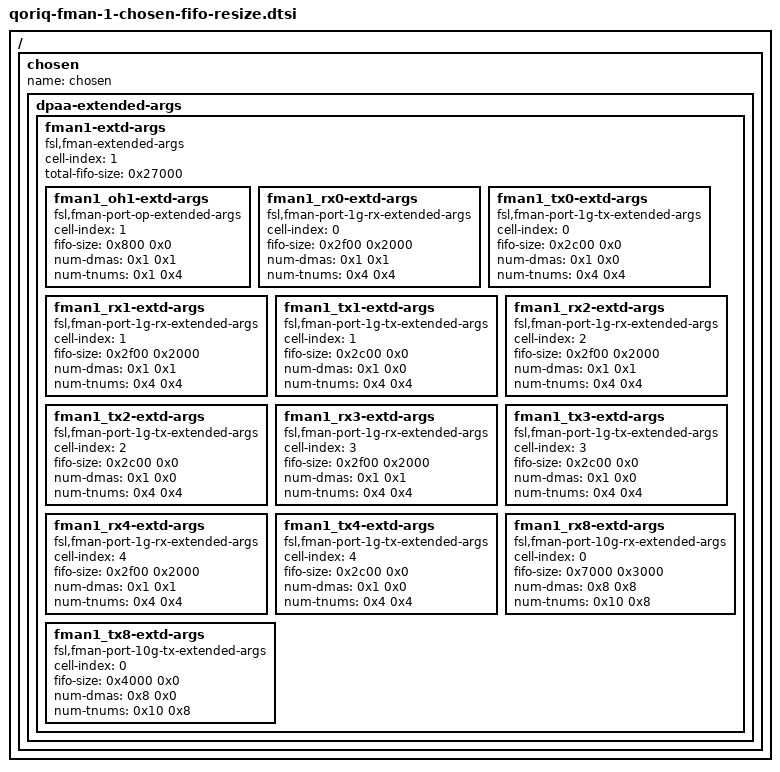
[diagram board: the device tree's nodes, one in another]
// SPDX-License-Identifier: (GPL-2.0+ OR BSD-3-Clause)
/*
 * Copyright 2018 NXP
 */

/ {
	chosen {
		name = "chosen";
		dpaa-extended-args {
			fman1-extd-args {
				cell-index = <1>;
				compatible = "fsl,fman-extended-args";
				total-fifo-size = <0x27000>;
				fman1_oh1-extd-args {
					cell-index = <1>;
					compatible = "fsl,fman-port-op-extended-args";
					fifo-size = <0x800 0x0>;
					num-dmas = <0x1 0x1>;
					num-tnums = <0x1 0x4>;
				};
				fman1_rx0-extd-args {
					cell-index = <0>;
					compatible = "fsl,fman-port-1g-rx-extended-args";
					fifo-size = <0x2f00 0x2000>;
					num-dmas = <0x1 0x1>;
					num-tnums = <0x4 0x4>;
				};
				fman1_tx0-extd-args {
					cell-index = <0>;
					compatible = "fsl,fman-port-1g-tx-extended-args";
					fifo-size = <0x2c00 0x0>;
					num-dmas = <0x1 0x0>;
					num-tnums = <0x4 0x4>;
				};
				fman1_rx1-extd-args {
					cell-index = <1>;
					compatible = "fsl,fman-port-1g-rx-extended-args";
					fifo-size = <0x2f00 0x2000>;
					num-dmas = <0x1 0x1>;
					num-tnums = <0x4 0x4>;
				};
				fman1_tx1-extd-args {
					cell-index = <1>;
					compatible = "fsl,fman-port-1g-tx-extended-args";
					fifo-size = <0x2c00 0x0>;
					num-dmas = <0x1 0x0>;
					num-tnums = <0x4 0x4>;
				};
				fman1_rx2-extd-args {
					cell-index = <2>;
					compatible = "fsl,fman-port-1g-rx-extended-args";
					fifo-size = <0x2f00 0x2000>;
					num-dmas = <0x1 0x1>;
					num-tnums = <0x4 0x4>;
				};
				fman1_tx2-extd-args {
					cell-index = <2>;
					compatible = "fsl,fman-port-1g-tx-extended-args";
					fifo-size = <0x2c00 0x0>;
					num-dmas = <0x1 0x0>;
					num-tnums = <0x4 0x4>;
				};
				fman1_rx3-extd-args {
					cell-index = <3>;
					compatible = "fsl,fman-port-1g-rx-extended-args";
					fifo-size = <0x2f00 0x2000>;
					num-dmas = <0x1 0x1>;
					num-tnums = <0x4 0x4>;
				};
				fman1_tx3-extd-args {
					cell-index = <3>;
					compatible = "fsl,fman-port-1g-tx-extended-args";
					fifo-size = <0x2c00 0x0>;
					num-dmas = <0x1 0x0>;
					num-tnums = <0x4 0x4>;
				};
				fman1_rx4-extd-args {
					cell-index = <4>;
					compatible = "fsl,fman-port-1g-rx-extended-args";
					fifo-size = <0x2f00 0x2000>;
					num-dmas = <0x1 0x1>;
					num-tnums = <0x4 0x4>;
				};
				fman1_tx4-extd-args {
					cell-index = <4>;
					compatible = "fsl,fman-port-1g-tx-extended-args";
					fifo-size = <0x2c00 0x0>;
					num-dmas = <0x1 0x0>;
					num-tnums = <0x4 0x4>;
				};
				fman1_rx8-extd-args {
					cell-index = <0>;
					compatible = "fsl,fman-port-10g-rx-extended-args";
					fifo-size = <0x7000 0x3000>;
					num-dmas = <0x8 0x8>;
					num-tnums = <0x10 0x8>;
				};
				fman1_tx8-extd-args {
					cell-index = <0>;
					compatible = "fsl,fman-port-10g-tx-extended-args";
					fifo-size = <0x4000 0x0>;
					num-dmas = <0x8 0x0>;
					num-tnums = <0x10 0x8>;
				};
			};
		};
	};
};
